# dm648_cslr_cpsw register map
Vendor: Texas Instruments
Peripheral module from a debugger description file.
Registers are 32-bit, access not given, reset 0x0 unless marked. A register's access mark holds for its fields unless they carry their own. Offsets are as the file gives them; lines under a group give offsets from that group; [hi:lo] are bit positions; {n}, {i} and the like mark numbered series; 'fields as' and 'values as' point back to an identical list; <NAME> marks a mode.

## CPSW — 3-Port Gigabit Switch Registers
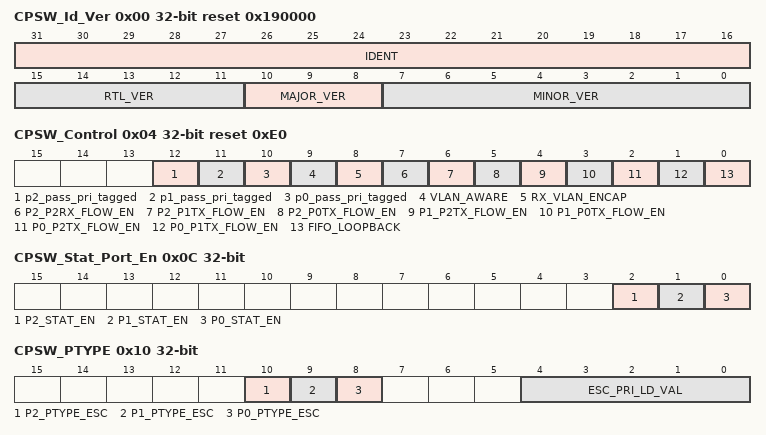
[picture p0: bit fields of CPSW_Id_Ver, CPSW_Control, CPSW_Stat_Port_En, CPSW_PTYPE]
0x00 CPSW_Id_Ver ro reset 0x190000 — version id register
  [31:16] IDENT — CPSW_3G Identification value
  [15:11] RTL_VER — CPSW_3G RTL_version register
  [10:8] MAJOR_VER — CPSW_3G Major version register
  [7:0] MINOR_VER — CPSW_3G Minor Version register
0x04 CPSW_Control reset 0xE0 — Control register
  [12] p2_pass_pri_tagged rw — Port 2 Pass Priority Tagged 0  Priority tagged packets have the zero VID replaced with the input port P2_PORT_VLAN[11:0] 1  Priority tagged packets are processed unchanged.
    0=? (Priority tagged packets have the zero VID replaced with the input port P2_PORT_VLAN[11:0]); 1=? (Priority tagged packets are processed unchanged.)
  [11] p1_pass_pri_tagged rw — Port 1 Pass Priority Tagged 0  Priority tagged packets have the zero VID replaced with the input port P1_PORT_VLAN[11:0] 1  Priority tagged packets are processed unchanged.
    0=? (Priority tagged packets have the zero VID replaced with the input port P1_PORT_VLAN[11:0]); 1=? (Priority tagged packets are processed unchanged.)
  [10] p0_pass_pri_tagged rw — Port 0 Pass Priority Tagged 0  Priority tagged packets have the zero VID replaced with the input port P0_PORT_VLAN[11:0] 1  Priority tagged packets are processed unchanged.
    0=? (Priority tagged packets have the zero VID replaced with the input port P0_PORT_VLAN[11:0]); 1=? (Priority tagged packets are processed unchanged.)
  [9] VLAN_AWARE rw — VLAN Aware Mode: 0  CPSW_3G is in the VLAN unaware mode. 1  CPSW_3G is in the VLAN aware mode.
    0=? (3pGSw is in the VLAN unaware mode); 1=? (3pGSw is in the VLAN aware mode)
  [8] RX_VLAN_ENCAP rw — Port 2 VLAN Encapsulation: 0  Port 2 receive packets (from CPSW_3G) are not VLAN encapsulated. 1 - Port 2 receive packets (from CPSW_3G) are VLAN encapsulated.
    0=? (Port 2 receive packets (from 3pGSw) are not VLAN encapsulated.); 1=? (Port 2 receive packets (from 3pGSw) are VLAN encapsulated.)
  [7] P2_P2RX_FLOW_EN rw — Port 2 transmit flow control enable from Port 2 receive FIFO: 0  No port 2 transmit flow control due to receive FIFO availability. 1  Issue port 2 transmit flow control when port 2 receive FIFO block usage is greater than or equal to the p2_p2rx_thresh value in the P2_TX_FLOW register.
    0=? (No port 2 transmit flow control due to receive FIFO availability); 1=? (Issue port 2 transmit flow control when port 2 receive FIFO block usage is greater than or equal to the p2_p2rx_thresh value in the P2_TX_FLOW register)
  [6] P2_P1TX_FLOW_EN rw — Port 2 transmit flow control enable from Port 1 transmit FIFO: 0  No port 2 transmit flow control due to port 1 transmit FIFO availability. 1  Issue port 2 transmit flow control when port 1 transmit FIFO block usage is greater than or equal to the p2_p1tx_thresh value in the P2_TX_FLOW register.
    0=? (No port 2 transmit flow control due to port 1 transmit FIFO availability); 1=? (Issue port 2 transmit flow control when port 1 transmit FIFO block usage is greater than or equal to the p2_p1tx_thresh value in the P2_TX_FLOW register)
  [5] P2_P0TX_FLOW_EN rw — Port 2 transmit flow control enable from Port 0 transmit FIFO: 0  No port 2 transmit flow control due to port 0 transmit FIFO availability. 1  Issue port 2 transmit flow control when port 0 transmit FIFO block usage is greater than or equal to the p2_p0tx_thresh value in the P2_TX_FLOW register.
    0=? (No port 2 transmit flow control due to port 0 transmit FIFO availability); 1=? (Issue port 2 transmit flow control when port 0 transmit FIFO block usage is greater than or equal to the p2_p0tx_thresh value in the P2_TX_FLOW register)
  [4] P1_P2TX_FLOW_EN rw — Port 1 receive flow control enable from Port 2 transmit FIFO: 0  No port 1 receive flow control due to port 2 transmit FIFO availability. 1  Issue port 1 receive flow control when port 2 transmit FIFO block usage is greater than or equal to the p1_p2tx_thresh value in the P1_TX_FLOW register (the rx_flow_en bit in the SL1_MacControl register must also be set).
    0=? (No port 1 receive flow control due to port 2 transmit FIFO availability); 1=? (Issue port 1 receive flow control when port 2 transmit FIFO block usage is greater than or equal to the p1_p2tx_thresh value in the P1_TX_FLOW register (the rx_flow_en bit in the SL1_MacControl register must also be set))
  [3] P1_P0TX_FLOW_EN rw — Port 1 receive flow control enable from Port 0 transmit FIFO: 0  No port 1 receive flow control due to port 0 transmit FIFO availability. 1  Issue port 1 receive flow control when port 0 transmit FIFO block usage is greater than or equal to the p1_p0tx_thresh value in the P1_TX_FLOW register (the rx_flow_en bit in the SL1_MacControl register must also be set).
    0=? (No port 1 receive flow control due to port 0 transmit FIFO availability); 1=? (Issue port 1 receive flow control when port 0 transmit FIFO block usage is greater than or equal to the p1_p0tx_thresh value in the P1_TX_FLOW register (the rx_flow_en bit in the SL1_MacControl register must also be set))
  [2] P0_P2TX_FLOW_EN rw — Port 0 receive flow control enable from Port 2 transmit FIFO: 0  No port 0 receive flow control due to port 2 transmit FIFO availability. 1  Issue port 0 receive flow control when port 2 transmit FIFO block usage is greater than or equal to the p0_p2tx_thresh value in the P0_TX_FLOW register (the rx_flow_en bit in the SL0_MacControl register must also be set).
    0=? (No port 0 receive flow control due to port 2 transmit FIFO availability); 1=? (Issue port 0 receive flow control when port 2 transmit FIFO block usage is greater than or equal to the p0_p2tx_thresh value in the P0_TX_FLOW register (the rx_flow_en bit in the SL0_MacControl register must also be set))
  [1] P0_P1TX_FLOW_EN rw — Port 0 receive flow control enable from Port 1 transmit FIFO: 0  No port 0 receive flow control due to port 1 transmit FIFO availability. 1  Issue port 0 receive flow control when port 1 transmit FIFO block usage is greater than or equal to the p0_p1tx_thresh value in the P0_TX_FLOW register (the rx_flow_en bit in the SL0_MacControl register must also be set).
    0=? (No port 0 receive flow control due to port 1 transmit FIFO availability); 1=? (Issue port 0 receive flow control when port 1 transmit FIFO block usage is greater than or equal to the p0_p1tx_thresh value in the P0_TX_FLOW register (the rx_flow_en bit in the SL0_MacControl register must also be set))
  [0] FIFO_LOOPBACK rw — FIFO Loopback Mode 0  Loopback is disabled 1  FIFO Loopback mode enabled. Each packet received is turned around and sent out on the same port's transmit path. Port 2 receive is fixed on channel zero. The RXSOFOVERRUN statistic will increment for every packet sent in FIFO loopback mode.
    0=? (Loopback is disabled); 1=? (FIFO Loopback mode enabled. Each packet received is turned around and sent out on the same port's transmit path. Port 2 receive is fixed on channel zero. The RXSOFOVERRUN statistic will increment for every packet sent in FIFO loopback mode)
0x08 CPSW_Soft_Reset — Software Reset Register
  [0] SOFT_RESET rw — Software reset  Writing a one to this bit causes the CPSW_3G logic to be reset. After writing a one to this bit, it may be polled to determine if the reset has occurred. If a one is read, the reset has not yet occurred. If a zero is read then reset has occurred.
    0=?
0x0C CPSW_Stat_Port_En — Statisitics Port Enable register
  [2] P2_STAT_EN rw — Port 2 Statistics Enable 0  Port 2 statistics are not enabled 1  Port 2 statistics are enabled. FIFO overruns (SOFOVERRUNS) are the only port 2 statistics that are enabled to be kept.
    0=? (Port 2 statistics are not enabled); 1=? (Port 2 statistics are enabled FIFO overruns (SOFOVERRUNS) are the only port 2 statistics that are enabled to be kept)
  [1] P1_STAT_EN rw — Port 1 (GMII 1 and Port 1 FIFO) Statistics Enable 0  Port 1 statistics are not enabled. 1  Port 1 statistics are enabled.
    0=? (Port 1 statistics are not enabled); 1=? (Port 1 statistics are enabled)
  [0] P0_STAT_EN rw — Port 0 (GMII 0 and Port 0 FIFO) Statistics Enable 0  Port 0 statistics are not enabled. 1  Port 0 statistics are enabled.
    0=? (Port 0 statistics are not enabled); 1=? (Port 0 statistics are enabled); 0=?
0x10 CPSW_PTYPE — Priority Type register
  [10] P2_PTYPE_ESC rw — Port 2 Priority Type Escalate  0  Port 2 priority type fixed 1  Port 2 priority type escalate
    1=? (Port 2 priority type escalate); 0=? (Port 2 priority type fixed)
  [9] P1_PTYPE_ESC rw — Port 1 Priority Type Escalate  0  Port 1 priority type fixed 1  Port 1 priority type escalate
    1=? (Port 1 priority type escalate); 0=? (Port 1 priority type fixed)
  [8] P0_PTYPE_ESC rw — Port 0 Priority Type Escalate  0  Port 0 priority type fixed 1  Port 0 priority type escalate
    1=? (Port 0 priority type escalate); 0=? (Port 0 priority type fixed)
  [4:0] ESC_PRI_LD_VAL rw — Escalate Priority Load Value When a port is in escalate priority, this is the number of higher priority packets sent before the next lower priority is allowed to send a packet. Escalate priority allows lower priority packets to be sent at a fixed rate relative to the next higher priority.
    0=?
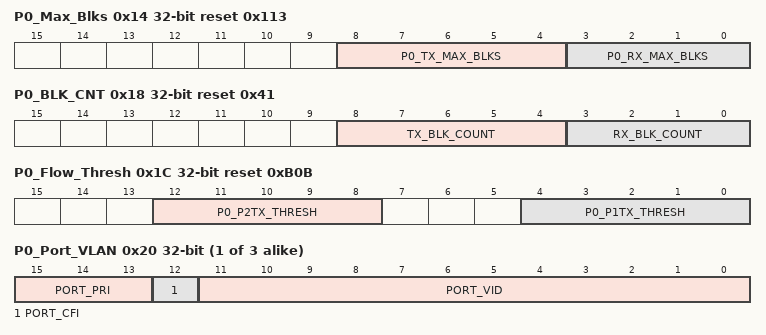
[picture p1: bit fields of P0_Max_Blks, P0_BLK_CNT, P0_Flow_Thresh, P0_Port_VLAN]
0x14 P0_Max_Blks reset 0x113 — Port 0 Max Blocks
  [8:4] P0_TX_MAX_BLKS rw — Transmit FIFO Maximum Blocks  This value is the maximum number of 1k memory blocks that may be allocated to the FIFO's logical transmit priority queues. 0x11 is the recommended value of p0_tx_max_blks unless the port is in fullduplex flow control mode. In flow control mode, the p0_rx_max_blks will need to increase in order to accept the required run out in fullduplex mode. This value will need to decrease by the amount of increase in p0_rx_max_blks. 0xe is the minimum value tx max blks.
    0=?
  [3:0] P0_RX_MAX_BLKS rw — Receive FIFO Maximum Blocks  This value is the maximum number of 1k memory blocks that may be allocated to the FIFO's logical receive queue. This value must be greater than or equal to 0x3. It should be increased In fullduplex flow control mode to 0x5 or 0x6 depending on the required runout space. The p0_tx_max_blks value must be decreased by the amount of increase in p0_rx_max_blks. 0x3 is the minimum value rx max blks and 0x6 is the maximum value.
    0=?
0x18 P0_BLK_CNT reset 0x41 — Port 0 Block Count
  [8:4] TX_BLK_COUNT ro — Port 0 Transmit Block Count Usage  This value is the number of blocks allocated to the FIFO logical transmit queues
    0=?
  [3:0] RX_BLK_COUNT ro — Port 0 Receive Block Count Usage  This value is the number of blocks allocated to the FIFO logical receive queues
    0=?; 0=?
0x1C P0_Flow_Thresh reset 0xB0B — Port 0 flow control threshold
  [12:8] P0_P2TX_THRESH rw — Port 0 Transmit Block Count Usage  This value is the number of blocks allocated to the FIFO logical transmit queues.
  [4:0] P0_P1TX_THRESH rw — Port 0 Receive Block Count Usage  This value is the number of blocks allocated to the FIFO logical receive queues.
{0x20+0x20*i} P{i}_Port_VLAN (i=0..2) — Port {i} VLAN
  [all] fields
    0=?
  [15:13] PORT_PRI rw — Port VLAN Priority (7 is highest priority)
  [12] PORT_CFI rw — Port CFI Bit
  [11:0] PORT_VID ro — Port VLAN ID
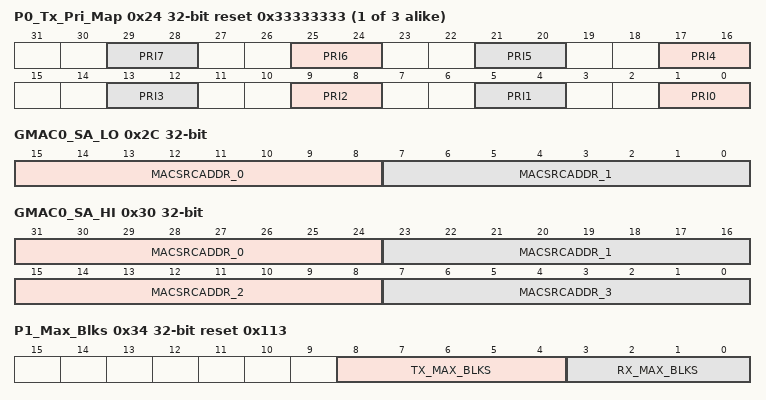
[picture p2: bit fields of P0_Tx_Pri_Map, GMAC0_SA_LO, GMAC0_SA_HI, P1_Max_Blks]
{0x24+0x20*i} P{i}_Tx_Pri_Map reset 0x33333333 (i=0..2) — P{i} Tx Header Priority to Switch Priority Mapping
  [4n+1:4n] PRI{n} rw (n=0..7) — Priority {n}  A packet header priority of {0x0+n} is given this switch queue pri.
0x28 GMAC0_Gap_Thresh reset 0xB — CPGMAC_SL0 Short Gap Threshold
  [4:0] P0_GAP_THRESH rw — Port 0 Short Gap Threshold.
0x2C GMAC0_SA_LO — CPGMAC_SL0 Source Address Low
  [15:8] MACSRCADDR_0 rw — Source Address Lower 8 bits (byte 0)
  [7:0] MACSRCADDR_1 rw — Source Address bits 15:8 (byte 1)
0x30 GMAC0_SA_HI rw — CPGMAC_SL0 Source Address Low
  [31:24] MACSRCADDR_0 — Source Address bits 23:16 (byte 2)
  [23:16] MACSRCADDR_1 — Source Address bits 31:23 (byte 3)
  [15:8] MACSRCADDR_2 — Source Address bits 39:32 (byte 4)
  [7:0] MACSRCADDR_3 — Source Address bits 47:40 (byte 5)
0x34 P1_Max_Blks reset 0x113 — Port 1 Max Blocks
  [8:4] TX_MAX_BLKS rw — Transmit FIFO Maximum Blocks  This value is the maximum number of 1k memory blocks that may be allocated to the FIFO's logical transmit priority queues. 0x11 is the recommended value of p1_tx_max_blks unless the port is in fullduplex flow control mode. In flow control mode, the p1_rx_max_blks will need to increase in order to accept the required run out in fullduplex mode. This value will need to decrease by the amount of increase in p1_rx_max_blks. 0xe is the minimum value tx max blks
    0=?
  [3:0] RX_MAX_BLKS rw — Receive FIFO Maximum Blocks  This value is the maximum number of 1k memory blocks that may be allocated to the FIFO's logical receive queue. This value must be greater than or equal to 0x3. It should be increased In fullduplex flow control mode to 0x5 or 0x6 depending on the required runout space. The p1_tx_max_blks value must be decreased by the amount of increase in p1_rx_max_blks. 0x3 is the minimum value rx max blks and 0x6 is the maximum value
    0=?
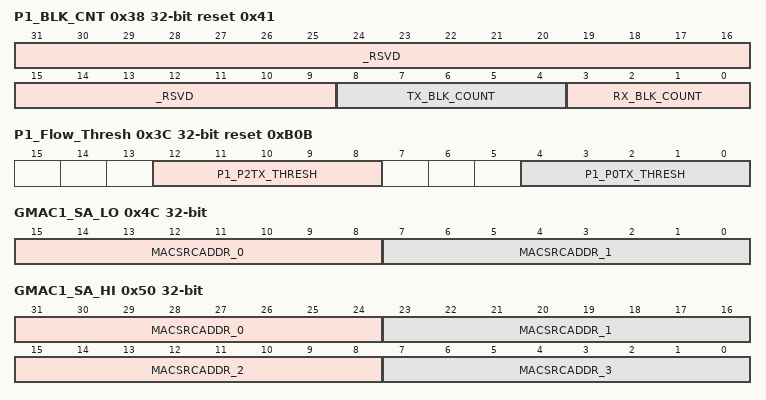
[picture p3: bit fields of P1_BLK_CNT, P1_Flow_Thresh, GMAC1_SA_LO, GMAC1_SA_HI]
0x38 P1_BLK_CNT reset 0x41 — Port 1 Block Count
  [31:9] _RSVD — (access N)
  [8:4] TX_BLK_COUNT ro — Port 1 Transmit Block Count Usage  This value is the number of blocks allocated to the FIFO logical transmit queues
    0=?
  [3:0] RX_BLK_COUNT ro — Port 1 Receive Block Count Usage  This value is the number of blocks allocated to the FIFO logical receive queues
    0=?; 0=?
0x3C P1_Flow_Thresh reset 0xB0B — Port 1 flow control threshold
  [12:8] P1_P2TX_THRESH rw — Port 2 transmit FIFO threshold value to trigger port 0 receive flow control.
  [4:0] P1_P0TX_THRESH rw — Port 1 transmit FIFO threshold value to trigger port 0 receive flow control.
0x48 GMAC1_Gap_Thresh reset 0xB — CPGMAC_SL0 Short Gap Threshold
  [4:0] P1_GAP_THRESH rw — Port 1 Short Gap Threshold.
0x4C GMAC1_SA_LO — CPGMAC_SL1 Source Address Low
  fields as GMAC0_SA_LO
0x50 GMAC1_SA_HI rw — CPGMAC_SL1 Source Address Low
  fields as GMAC0_SA_HI
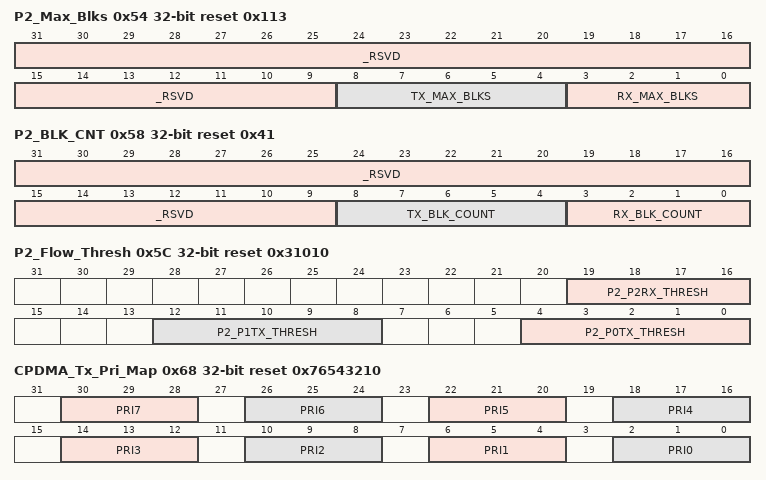
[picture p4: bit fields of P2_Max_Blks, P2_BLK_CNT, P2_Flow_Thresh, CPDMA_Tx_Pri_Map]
0x54 P2_Max_Blks reset 0x113 — Port 2 Max Blocks
  [31:9] _RSVD — (access N)
  [8:4] TX_MAX_BLKS rw — Transmit FIFO Maximum Blocks  This value is the maximum number of 1k memory blocks that may be allocated to the FIFO's logical transmit priority queues. 0x10 is the recommended value of p2_tx_max_blks. Port 2 should remain in flow control mode. 0xe is the minimum value tx max blks
    0=?
  [3:0] RX_MAX_BLKS rw — Receive FIFO Maximum Blocks  This value is the maximum number of 1k memory blocks that may be allocated to the FIFO's logical receive queue. 0x4 is the recommended value. 0x3 is the minimum value rx max blks and 0x6 is the maximum value
    0=?
0x58 P2_BLK_CNT reset 0x41 — Port 2 Block Count
  [31:9] _RSVD — (access N)
  [8:4] TX_BLK_COUNT ro — Port 2 Transmit Block Count Usage  This value is the number of blocks allocated to the FIFO logical transmit queues
    0=?
  [3:0] RX_BLK_COUNT ro — Port 2 Receive Block Count Usage  This value is the number of blocks allocated to the FIFO logical receive queues
    0=?; 0=?
0x5C P2_Flow_Thresh reset 0x31010 — Port 2 flow control threshold
  [19:16] P2_P2RX_THRESH rw — Port 2 receive FIFO threshold value to trigger port 2 transmit flow control. 0x3 is the recommended value
  [12:8] P2_P1TX_THRESH rw — Port 1 transmit FIFO threshold value to trigger port 2 transmit flow control. 0xb is the recommended value
  [4:0] P2_P0TX_THRESH rw — Port 0 transmit FIFO threshold value to trigger port 2 transmit flow control. 0xb is the recommended value
0x68 CPDMA_Tx_Pri_Map reset 0x76543210 — CPDMA TX Pkt Pri to Header Pri Mapping
  [30:28] PRI7 rw — Priority 7  A packet priority of 0x7 is given this header packet pri.
  [4n+2:4n] PRI{n} rw (n=0..6) — Priority {n}  A packet priority of {0x0+n} is given this header queue pri.
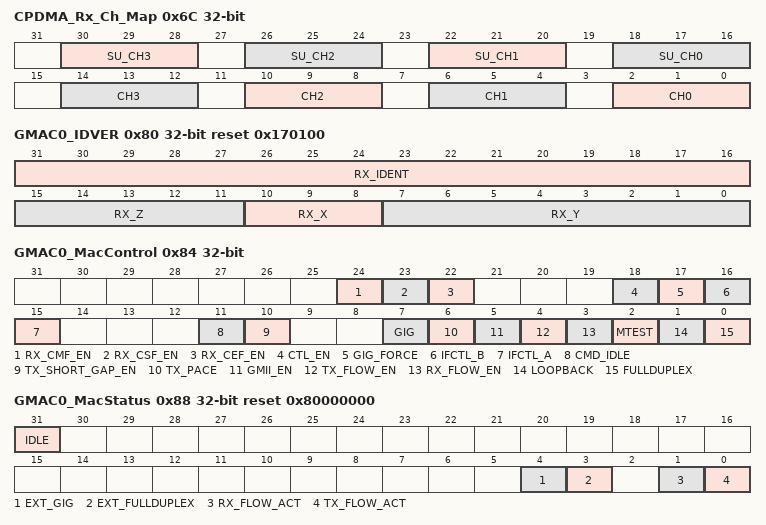
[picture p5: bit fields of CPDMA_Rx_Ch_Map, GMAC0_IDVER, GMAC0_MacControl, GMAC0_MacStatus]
0x6C CPDMA_Rx_Ch_Map — P2 Tx Switch Pri to CPDMA Rx Channel
  [30:28] SU_CH3 rw — Channel 3  Supervisory packet of switch pri 0x3 is mapped to this CPDMA RX channel
  [26:24] SU_CH2 rw — Channel 2  Supervisory packet of switch pri 0x2 is mapped to this CPDMA RX channel
  [22:20] SU_CH1 rw — Channel 1  Supervisory packet of switch pri 0x1 is mapped to this CPDMA RX channel
  [18:16] SU_CH0 rw — Channel 0  Supervisory packet of switch pri 0x1 is mapped to this CPDMA RX channel
  [4n+2:4n] CH{n} rw (n=0..3) — Channel {n}  Switch pri of {0x0+n} is mapped to this CPDMA Rx Channel
0x80 GMAC0_IDVER ro reset 0x170100 — CPGMAC_SL0 ID/Version Register
  [31:16] RX_IDENT — RX Identification value
  [15:11] RX_Z — RX Z value
  [10:8] RX_X — Rx X Value
  [7:0] RX_Y — Rx Y value
0x84 GMAC0_MacControl — CPGMAC_SL0 Mac Control Register
  [24] RX_CMF_EN rw — RX Copy MAC Control Frames Enable  Enables MAC control frames to be transferred to memory. MAC control frames are normally acted upon (if enabled), but not copied to memory. MAC control frames that are pause frames will be acted upon if enabled in the MacControl register, regardless of the value of rx_cmf_en. Frames transferred to memory due to rx_cmf_en will have the control bit set in their EOP buffer descriptor
    1=ENABLE (MAC control frames are transferred to memory); 0=DISABLE (MAC control frames are filtered (but acted upon if enabled))
  [23] RX_CSF_EN rw — RX Copy Short Frames Enable  Enables frames or fragments shorter than 64 bytes to be copied to memory. Frames transferred to memory due to rx_csf_en will have the fragment or undersized bit set in their EOP buffer descriptor. Fragments are short frames that contain CRC/align/code errors and undersized are short frames without errors
    1=ENABLE (Short frames are transferred to memory); 0=DISABLE (Short frames are filtered)
  [22] RX_CEF_EN rw — RX Copy Error Frames Enable  Enables frames containing errors to be transferred to memory. The appropriate error bit will be set in the frame EOP buffer descriptor. Frames containing errors will be filtered when rx_cef _en is not set
    1=ENABLE (Frames containing errors are transferred to memory); 0=DISABLE (Frames containing errors are filtered)
  [18] CTL_EN rw — Control Enable  Enables the fullduplex and gigabit mode to be selected from the FULLDUPLEX_IN and GIG_IN input signals and not from the fullduplex and gig bits in this register. The FULLDUPLEX_MODE bit reflects the actual fullduplex mode selected.
    1=ENABLE; 0=DISABLE
  [17] GIG_FORCE rw — Gigabit Mode Force  This bit is used to force the CPGMAC_SL into gigabit mode if the input GMII_MTCLK has been stopped by the PHY
    1=ENABLE; 0=DISABLE
  [16] IFCTL_B rw — Interface Control B  Intended as a general purpose output bit to be used to control external gaskets associated with the GMII (GMII to RGMII etc)
    1=ENABLE; 0=DISABLE
  [15] IFCTL_A rw — Interface Control A  Intended as a general purpose output bit to be used to control external gaskets associated with the GMII (GMII to RGMII etc)
    1=ENABLE; 0=DISABLE
  [11] CMD_IDLE rw — Command Idle
    0=? (Idle not commanded); 1=? (Idle Commanded (read idle in MacStatus))
  [10] TX_SHORT_GAP_EN rw — Transmit Short Gap Enable
    1=ENABLE (Transmit with a short IPG (when TX_SHORT_GAP input is asserted) is enabled); 0=DISABLE (Transmit with a short IPG is disabled)
  [7] GIG rw — Gigabit Mode
    1=ENABLE (Gigabit mode (full duplex only)); 0=DISABLE (10/100 mode)
  [6] TX_PACE rw — Transmit Pacing
    1=ENABLE (Transmit Pacing Enabled); 0=DISABLE (Transmit Pacing Disabled)
  [5] GMII_EN rw — GMII Enable
    1=ENABLE (GMII RX and TX released from reset); 0=DISABLE (GMII RX and TX held in reset)
  [4] TX_FLOW_EN rw — Transmit Flow Control Enable  Determines if incoming pause frames are acted upon in full-duplex mode. Incoming pause frames are not acted upon in half-duplex mode regardless of this bit setting. The RX_MBP_Enable bits determine whether or not received pause frames are transferred to memory
    1=ENABLE (Transmit Flow Control Enabled . Full-duplex mode  Incoming pause frames are acted upon); 0=DISABLE (Transmit Flow Control Disabled. Full-duplex mode  Incoming pause frames are not acted upon)
  [3] RX_FLOW_EN rw — Receive Flow Control Enable
    1=ENABLE (Receive Flow Control Enabled Half-duplex mode  Collisions are initiated when receive flow control is triggered. Full-duplex mode  Outgoing pause frames are sent when receive flow control is triggered); 0=DISABLE (Receive Flow Control Disabled Half-duplex mode  No flow control generated collisions are sent. Full-duplex mode  No outgoing pause frames are sent)
  [2] MTEST rw — Manufacturing Test mode  This bit must be set to allow writes to the Backoff_Test and PauseTimer registers
  [1] LOOPBACK rw — Loop Back Mode  Loopback mode forces internal fullduplex mode regardless of whether the fullduplex bit is set or not. The loopback bit should be changed only when GMII_en is deasserted
    1=ENABLE (Loop Back Mode enabled); 0=DISABLE (Not looped back)
  [0] FULLDUPLEX rw — Full Duplex mode  Gigabit mode forces fullduplex mode regardless of whether the fullduplex bit is set or not. The FULLDUPLEX_OUT output is the value of this register bit
    1=ENABLE (full duplex mode); 0=DISABLE (half duplex mode)
0x88 GMAC0_MacStatus reset 0x80000000 — CPGMAC_SL0 Mac Status Register
  [31] IDLE ro — CPGMAC_SL IDLE  The CPGMAC_SL is in the idle state (valid after an idle command)
    1=? (The CPGMAC_SL is in the idle state); 0=? (The CPGMAC_SL is not in the idle state)
  [4] EXT_GIG ro — External GIG  This is the value of the EXT_GIG input bit
    0=?
  [3] EXT_FULLDUPLEX ro — External Fullduplex  This is the value of the EXT_FULLDUPLEX input bit
    0=?
  [1] RX_FLOW_ACT ro — Receive Flow Control Active  When asserted, indicates that receive flow control is enabled and triggered
  [0] TX_FLOW_ACT ro — Transmit Flow Control Active  When asserted, this bit indicates that the pause time period is being observed for a received pause frame. No new transmissions will begin while this bit is asserted except for the transmission of pause frames. Any transmission in progress when this bit is asserted will complete
0x8C GMAC0_Soft_Reset — CPGMAC_SL0 Mac Soft Reset Register
  [0] SOFT_RESET rw — Software reset  Writing a one to this bit causes the CPGMAC_SL logic to be reset. After writing a one to this bit, it may be polled to determine if the reset has occurred. If a one is read, the reset has not yet occurred. If a zero is read then reset has occurred
    0=?; 0=?
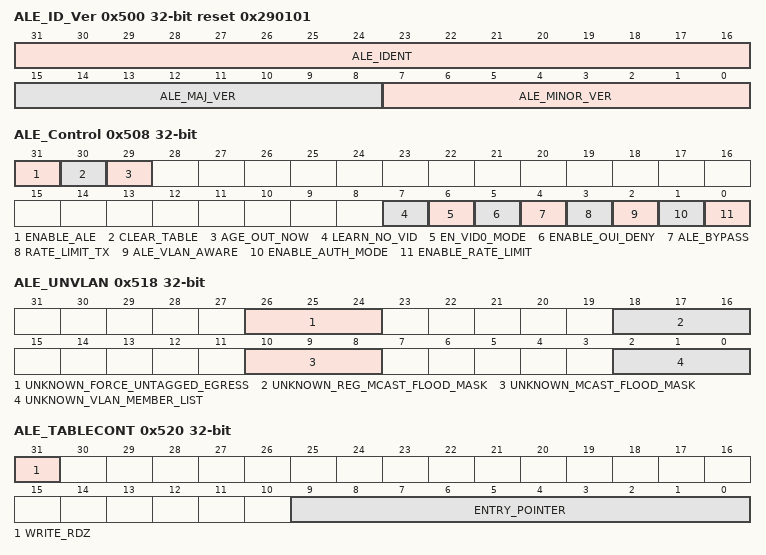
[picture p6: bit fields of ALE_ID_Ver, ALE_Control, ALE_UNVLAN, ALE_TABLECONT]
0x500 ALE_ID_Ver ro reset 0x290101 — ALE ID Version Register
  [all] fields
    0=?
  [31:16] ALE_IDENT — ALE Identification Value
  [15:8] ALE_MAJ_VER — ALE Major Version Value
  [7:0] ALE_MINOR_VER — ALE Minor Version Value
0x508 ALE_Control
  [31] ENABLE_ALE rw — Enable ALE - 0  Drop all packets 1  Enable ALE packet processing
    values as GMAC0_MacStatus.IDLE
  [30] CLEAR_TABLE rw — Clear ALE address table  Setting this bit causes the ALE hardware to write all table bit values to zero. Software must perform a clear table operation as part of the ALE setup/configuration process. Setting this bit causes all ALE accesses to be held up for 64 clocks while the clear is performed. Access to all ALE registers will be blocked (wait states) until the 64 clocks have completed. This bit cannot be read as one because the read is blocked until the clear table is completed at which time this bit is cleared to zero.
    0=?
  [29] AGE_OUT_NOW rw — Age Out Address Table Now  Setting this bit causes the ALE hardware to remove (free up) any ageable table entry that does not have a set touch bit. This bit is cleared when the age out process has completed. This bit may be read. The age out process takes 4096 clocks best case (no ale packet processing during ageout) and 66550 clocks absolute worst case.
    0=?
  [7] LEARN_NO_VID rw — Learn No VID  0  VID is learned with the source address 1  VID is not learned with the source address (source address is not tied to VID).
  [6] EN_VID0_MODE rw — Enable VLAN ID = 0 Mode 0  Process the packet with VID = PORT_VLAN[11:0]. 1  Process the packet with VID = 0.
  [5] ENABLE_OUI_DENY rw — Enable OUI Deny Mode  When set this bit indicates that a packet with a non OUI table entry matching source address will be dropped to the host unless the destination address matches a multicast table entry with the super bit set.
  [4] ALE_BYPASS rw — ALE Bypass  This bit causes all packets to be forwarded only to the host port. Packets from CPGMAC_SL1 will be designated as supervisory so that they may be sent to a different CPDMA channel than packets from CPGMAC_SL0. 0  ALE is in normal mode. 1  ALE is in bypass mode.
  [3] RATE_LIMIT_TX rw — Rate Limit Transmit mode - 0  Broadcast and multicast rate limit counters are received port based 1  Broadcast and multicast rate limit counters are transmit port based.
  [2] ALE_VLAN_AWARE rw — ALE VLAN Aware  Determines what is done if VLAN not found. 0  Flood if VLAN not found 1  Drop packet if VLAN not found
  [1] ENABLE_AUTH_MODE rw — Enable MAC Authorization Mode  Mac authorization mode requires that all table entries be made by the host software. There are no learned address in authorization mode and the packet will be dropped if the source address is not found (and the destination address is not a multicast address with the super table entry bit set). 0  The ALE is not in MAC authorization mode 1  The ALE is in MAC authorization mode
  [0] ENABLE_RATE_LIMIT rw — Enable Broadcast and Multicast Rate Limit 0  Broadcast/Multicast rates not limited 1  Broadcast/Multicast packet reception limited to the port control register rate limit fields.
0x510 ALE_PreScale
  [19:0] ALE_PRESCALE rw — ALE Prescale Register  The input clock is divided by this value for use in the multicast/broadcast rate limiters. The minimum operating value is 0x10. The prescaler is off when the value is zero.
    0=?
0x518 ALE_UNVLAN — ALE UnKnon VLAN Register
  [26:24] UNKNOWN_FORCE_UNTAGGED_EGRESS rw — Unknown VLAN Force Untagged Egress (except on port 2)
    0=?
  [18:16] UNKNOWN_REG_MCAST_FLOOD_MASK rw — Unknown VLAN Registered Multicast Flood Mask
    0=?
  [10:8] UNKNOWN_MCAST_FLOOD_MASK rw — Unknown VLAN Multicast Flood Mask
  [2:0] UNKNOWN_VLAN_MEMBER_LIST rw
0x520 ALE_TABLECONT — ALE Table Control Register
  [31] WRITE_RDZ rw — Write Bit  This bit is always read as zero. Writing a 1 to this bit causes the three table word register values to be written to the entry_pointer location in the address table. Writing a 0 to this bit causes the three table word register values to be loaded from the entry_pointer location in the address table so that they may be subsequently read. A read of any ALE address location will be stalled until the read or write has completed.
    values as GMAC0_MacStatus.IDLE
  [9:0] ENTRY_POINTER rw — Table Entry Pointer - The entry_pointer contains the table entry value that will be read/written with accesses to the table word registers.
0x534 ALE_TABLEWORD2
  [3:0] ENTRY_67_64 rw — Table entry bits 67:64
    0=?
0x538 ALE_TABLEWORD1 rw
  [31:0] ENTRY_63_32 — Table entry bits 63:32
    0=?
0x53C ALE_TABLEWORD0 rw
  [31:0] ENTRY_31_0 — Table entry bits 31:0
    0=?
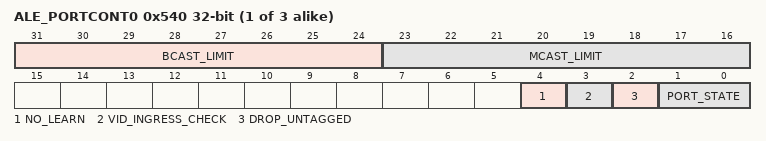
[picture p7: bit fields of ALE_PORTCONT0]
{0x540+4i} ALE_PORTCONT{i} (i=0..2) — ALE Port Control {i} Register
  [31:24] BCAST_LIMIT rw — Broadcast Packet Rate Limit - Each prescale pulse loads this field into the port broadcast rate limit counter. The port counters are decremented with each packet received or transmitted depending on whether the mode is transmit or receive. If the counters decrement to zero, then further packets are rate limited until the next prescale pulse. Broadcast rate limiting is enabled by a non-zero value in this field
    values as GMAC0_MacStatus.IDLE
  [23:16] MCAST_LIMIT rw — Multicast Packet Rate Limit  Each prescale pulse loads this field into the port multicast rate limit counter. The port counters are decremented with each packet received or transmitted depending on whether the mode is transmit or receive. If the counters decrement to zero, then further packets are rate limited until the next prescale pulse. Multicast rate limiting is enabled by a non-zero value in this field.
    0=?
  [4] NO_LEARN rw — No Learn Mode  When set the port is disabled from learning or updating source addresses.
    0=?
  [3] VID_INGRESS_CHECK rw — VLAN ID Ingress Check  If VLAN not found then drop the packet. Packets with an unknown (default) VLAN will be dropped.
    0=?
  [2] DROP_UNTAGGED rw — Drop Untagged Packets  Drop non-VLAN tagged ingress packets.
  [1:0] PORT_STATE rw — Port State 0  Disabled 1  Blocked 2  Learn 3  Forward
